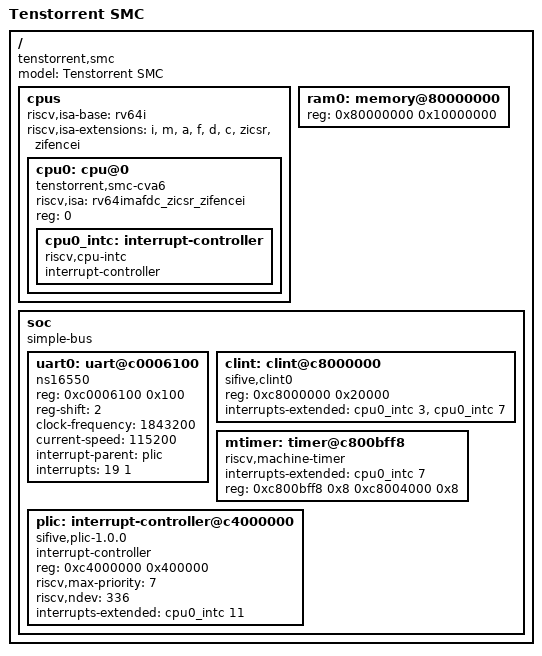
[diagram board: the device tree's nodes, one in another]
/*
 * SPDX-License-Identifier: Apache-2.0
 *
 * Tenstorrent SMC (smc-vp) SoC skeleton.
 *
 * Addresses match sw/smc-vp-tests/common/smc_common.h and
 * vp/platform/smc/src/smc_platform.cpp.
 */

/dts-v1/;

/ {
	#address-cells = <1>;
	#size-cells = <1>;
	compatible = "tenstorrent,smc";
	model = "Tenstorrent SMC";

	cpus {
		#address-cells = <1>;
		#size-cells = <0>;
		riscv,isa-base = "rv64i";
		riscv,isa-extensions = "i", "m", "a", "f", "d", "c",
				       "zicsr", "zifencei";

		cpu0: cpu@0 {
			device_type = "cpu";
			compatible = "tenstorrent,smc-cva6", "riscv";
			riscv,isa = "rv64imafdc_zicsr_zifencei";
			reg = <0>;
			status = "okay";
			cpu0_intc: interrupt-controller {
				compatible = "riscv,cpu-intc";
				#address-cells = <0>;
				#interrupt-cells = <1>;
				interrupt-controller;
			};
		};
	};

	ram0: memory@80000000 {
		device_type = "memory";
		reg = <0x80000000 0x10000000>;
	};

	soc {
		#address-cells = <1>;
		#size-cells = <1>;
		compatible = "simple-bus";
		ranges;

		uart0: uart@c0006100 {
			compatible = "ns16550";
			reg = <0xc0006100 0x100>;
			reg-shift = <2>;
			clock-frequency = <1843200>;
			current-speed = <115200>;
			interrupt-parent = <&plic>;
			interrupts = <19 1>;
			status = "okay";
		};

		clint: clint@c8000000 {
			compatible = "sifive,clint0";
			reg = <0xc8000000 0x20000>;
			interrupts-extended = <&cpu0_intc 3 &cpu0_intc 7>;
		};

		mtimer: timer@c800bff8 {
			compatible = "riscv,machine-timer";
			interrupts-extended = <&cpu0_intc 7>;
			reg = <0xc800bff8 0x8 0xc8004000 0x8>;
			reg-names = "mtime", "mtimecmp";
		};

		plic: interrupt-controller@c4000000 {
			compatible = "sifive,plic-1.0.0";
			#address-cells = <0>;
			#interrupt-cells = <2>;
			interrupt-controller;
			reg = <0xc4000000 0x400000>;
			riscv,max-priority = <7>;
			riscv,ndev = <336>;
			interrupts-extended = <&cpu0_intc 11>;
		};
	};
};
